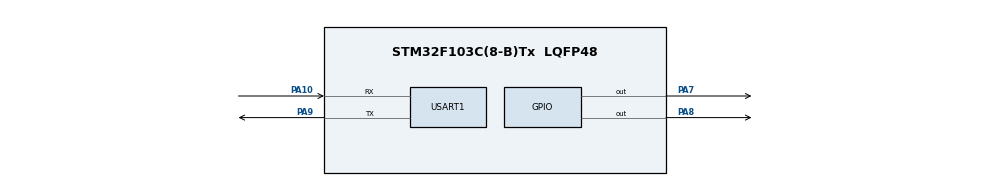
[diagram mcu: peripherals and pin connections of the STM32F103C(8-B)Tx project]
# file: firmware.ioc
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Mcu.Family=STM32F1
Mcu.Name=STM32F103C(8-B)Tx
Mcu.Package=LQFP48
NVIC.PriorityGroup=NVIC_PRIORITYGROUP_2
NVIC.USART1_IRQn=true\:0\:0\:false\:false\:true\:true\:true
PA10.Mode=Asynchronous
PA10.Signal=USART1_RX
PA13.Mode=Serial_Wire
PA13.Signal=SYS_JTMS-SWDIO
PA14.Mode=Serial_Wire
PA14.Signal=SYS_JTCK-SWCLK
PA7.Signal=GPIO_Output
PA8.Signal=GPIO_Output
PA9.Mode=Asynchronous
PA9.Signal=USART1_TX
PD0-OSC_IN.Mode=HSE-External-Oscillator
PD0-OSC_IN.Signal=RCC_OSC_IN
PD1-OSC_OUT.Mode=HSE-External-Oscillator
PD1-OSC_OUT.Signal=RCC_OSC_OUT
ProjectManager.HeapSize=0x200
ProjectManager.StackSize=0x400
ProjectManager.TargetToolchain=Makefile
RCC.AHBFreq_Value=48000000
RCC.APB1CLKDivider=RCC_HCLK_DIV4
RCC.APB1Freq_Value=12000000
RCC.APB1TimFreq_Value=24000000
RCC.APB2Freq_Value=48000000
RCC.APB2TimFreq_Value=48000000
RCC.HCLKFreq_Value=48000000
RCC.PLLMUL=RCC_PLL_MUL6
RCC.PLLSourceVirtual=RCC_PLLSOURCE_HSE
RCC.SYSCLKFreq_VALUE=48000000
RCC.SYSCLKSource=RCC_SYSCLKSOURCE_PLLCLK
RCC.USBFreq_Value=48000000
USART1.VirtualMode=VM_ASYNC
board=custom

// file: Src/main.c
/* USER CODE BEGIN Header */
/**
  ******************************************************************************
  * @file           : main.c
  * @brief          : Main program body
  ******************************************************************************
  * @attention
  *
  * <h2><center>&copy; Copyright (c) 2020 STMicroelectronics.
  * All rights reserved.</center></h2>
  *
  * This software component is licensed by ST under BSD 3-Clause license,
  * the "License"; You may not use this file except in compliance with the
  * License. You may obtain a copy of the License at:
  *                        opensource.org/licenses/BSD-3-Clause
  *
  ******************************************************************************
  */
/* USER CODE END Header */

#include "main.h"
#include "usart.h"
#include "gpio.h"

/* USER CODE BEGIN Includes */
#include "sys_time.h"
#include "stdio.h"
// #include "dap_agent.h"
#include "soft_spi.h"
#include "lis3dh.h"
/* USER CODE END Includes */

void SystemClock_Config(void);

int main(void)
{

  /* MCU Configuration--------------------------------------------------------*/

  /* Reset of all peripherals, Initializes the Flash interface and the Systick. */

  LL_APB2_GRP1_EnableClock(LL_APB2_GRP1_PERIPH_AFIO);
  LL_APB1_GRP1_EnableClock(LL_APB1_GRP1_PERIPH_PWR);

  NVIC_SetPriorityGrouping(NVIC_PRIORITYGROUP_2);

  /* System interrupt init*/

  /** NOJTAG: JTAG-DP Disabled and SW-DP Enabled
  */
  LL_GPIO_AF_Remap_SWJ_NOJTAG();

  /* Configure the system clock */
  SystemClock_Config();

  /* Initialize all configured peripherals */
  MX_GPIO_Init();
  MX_USART1_UART_Init();
  /* USER CODE BEGIN 2 */
  LL_SYSTICK_EnableIT();
  LL_USART_EnableIT_RXNE(USART1);
  /* USER CODE END 2 */

  /* Infinite loop */
  /* USER CODE BEGIN WHILE */
  // DapAgent_Init();
  SoftSpi_Init();
  Lis3dh_Init();
  while (1)
  {
    /* USER CODE END WHILE */

    /* USER CODE BEGIN 3 */

    static uint64_t lastTime = 0;
    if (TimeElapsed(lastTime) > 1000)
    {
      SetToCurTime(&lastTime);
      Lis3dh_Test();
      // DapAgent_Test();
    }
  }
  /* USER CODE END 3 */
}

void SystemClock_Config(void)
{
  LL_FLASH_SetLatency(LL_FLASH_LATENCY_1);

  if (LL_FLASH_GetLatency() != LL_FLASH_LATENCY_1)
  {
    Error_Handler();
  }
  LL_RCC_HSE_Enable();

  /* Wait till HSE is ready */
  while (LL_RCC_HSE_IsReady() != 1)
  {
  }
  LL_RCC_PLL_ConfigDomain_SYS(LL_RCC_PLLSOURCE_HSE_DIV_1, LL_RCC_PLL_MUL_6);
  LL_RCC_PLL_Enable();

  /* Wait till PLL is ready */
  while (LL_RCC_PLL_IsReady() != 1)
  {
  }
  LL_RCC_SetAHBPrescaler(LL_RCC_SYSCLK_DIV_1);
  LL_RCC_SetAPB1Prescaler(LL_RCC_APB1_DIV_4);
  LL_RCC_SetAPB2Prescaler(LL_RCC_APB2_DIV_1);
  LL_RCC_SetSysClkSource(LL_RCC_SYS_CLKSOURCE_PLL);

  /* Wait till System clock is ready */
  while (LL_RCC_GetSysClkSource() != LL_RCC_SYS_CLKSOURCE_STATUS_PLL)
  {
  }
  LL_Init1msTick(48000000);
  LL_SetSystemCoreClock(48000000);
}

void Error_Handler(void)
{
}

/************************ (C) COPYRIGHT STMicroelectronics *****END OF FILE****/
